# ESP32-C5-LP register map
Vendor: ESPRESSIF SYSTEMS (SHANGHAI) CO., LTD.; Series: ESP32 C-Series; File version: 1
CPU: RV32IMAC r0p0, little endian, no MPU, no FPU, 0 interrupt priority bits
Address unit: 32 bits
Registers are 32-bit, read-write, reset 0x0 unless marked. A register's access mark holds for its fields unless they carry their own. Offsets are from the block's base; [hi:lo] are bit positions; {n}, {i} and the like mark numbered series.

## LP_APM0 — LP_APM0 Peripheral
Base 0x600B3800
0x00 REGION_FILTER_EN reset 0x1 — Region filter enable register
  [3:0] REGION_FILTER_EN — Configure bit 0 (0-3) to enable region 0.\\ 0: disable \\ 1: enable \\
{0x4+0xC*i} REGION{i}_ADDR_START (i=0..3) — Region address register
  [31:0] REGION_ADDR_START — Configures start address of region %s.
{0x8+0xC*i} REGION{i}_ADDR_END (i=0..3) reset 0xFFFFFFFF — Region address register
  [31:0] REGION_ADDR_END — Configures end address of region %s.
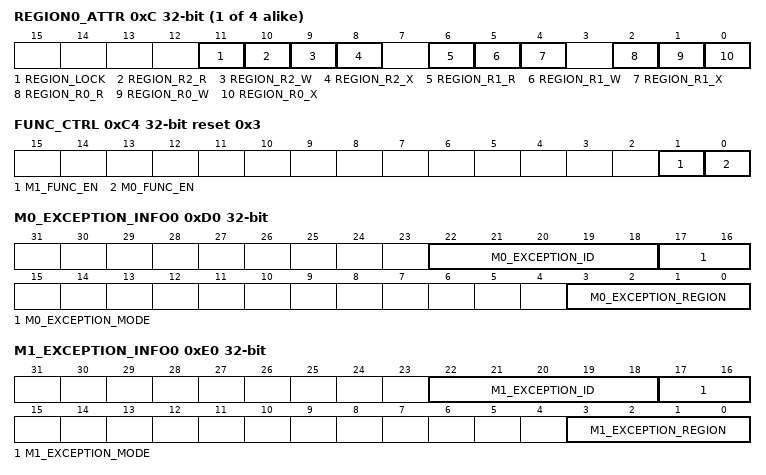
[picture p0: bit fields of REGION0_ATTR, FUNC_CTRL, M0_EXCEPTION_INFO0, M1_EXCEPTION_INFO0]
{0xC+0xC*i} REGION{i}_ATTR (i=0..3) — Region access authority attribute register
  [11] REGION_LOCK — Set 1 to lock region0 configuration
  [10] REGION_R2_R — Configures the read authority of REE_MODE 2 in region %s.
  [9] REGION_R2_W — Configures the write authority of REE_MODE 2 in region %s.
  [8] REGION_R2_X — Configures the execution authority of REE_MODE 2 in region %s.
  [6] REGION_R1_R — Configures the read authority of REE_MODE 1 in region %s.
  [5] REGION_R1_W — Configures the write authority of REE_MODE 1 in region %s.
  [4] REGION_R1_X — Configures the execution authority of REE_MODE 1 in region %s.
  [2] REGION_R0_R — Configures the read authority of REE_MODE 0 in region %s.
  [1] REGION_R0_W — Configures the write authority of REE_MODE 0 in region %s.
  [0] REGION_R0_X — Configures the execution authority of REE_MODE 0 in region %s.
0xC4 FUNC_CTRL reset 0x3 — APM function control register
  [1] M1_FUNC_EN — PMS M1 function enable
  [0] M0_FUNC_EN — PMS M0 function enable
0xC8 M0_STATUS ro
  [1:0] M0_EXCEPTION_STATUS — Represents exception status.\\ bit0: 1 represents authority_exception \\ bit1: 1 represents space_exception \\
0xCC M0_STATUS_CLR wo — M0 status clear register
  [0] M0_EXCEPTION_STATUS_CLR — Configures to clear exception status.
0xD0 M0_EXCEPTION_INFO0 ro
  [22:18] M0_EXCEPTION_ID — Represents exception id information.
  [17:16] M0_EXCEPTION_MODE — Represents exception mode.
  [3:0] M0_EXCEPTION_REGION — Represents exception region.
0xD4 M0_EXCEPTION_INFO1 ro
  [31:0] M0_EXCEPTION_ADDR — Represents exception addr.
0xD8 M1_STATUS ro
  [1:0] M1_EXCEPTION_STATUS — Represents exception status.\\ bit0: 1 represents authority_exception \\ bit1: 1 represents space_exception \\
0xDC M1_STATUS_CLR wo — M1 status clear register
  [0] M1_EXCEPTION_STATUS_CLR — Configures to clear exception status.
0xE0 M1_EXCEPTION_INFO0 ro
  [22:18] M1_EXCEPTION_ID — Represents exception id information.
  [17:16] M1_EXCEPTION_MODE — Represents exception mode.
  [3:0] M1_EXCEPTION_REGION — Represents exception region.
0xE4 M1_EXCEPTION_INFO1 ro
  [31:0] M1_EXCEPTION_ADDR — Represents exception addr.
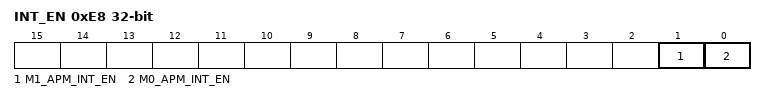
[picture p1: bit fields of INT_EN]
0xE8 INT_EN — APM interrupt enable register
  [1] M1_APM_INT_EN — Configures to enable APM M1 interrupt.\\ 0: disable \\ 1: enable \\
  [0] M0_APM_INT_EN — Configures to enable APM M0 interrupt.\\ 0: disable \\ 1: enable \\
0xEC CLOCK_GATE reset 0x1 — clock gating register
  [0] CLK_EN — Configures whether to keep the clock always on.\\ 0: enable automatic clock gating \\ 1: keep the clock always on \\
0xFC DATE reset 0x2212160 — Version control register
  [27:0] DATE — Version control register.

## LP_I2C_ANA_MST — LP_I2C_ANA_MST Peripheral
Base 0x600B2400
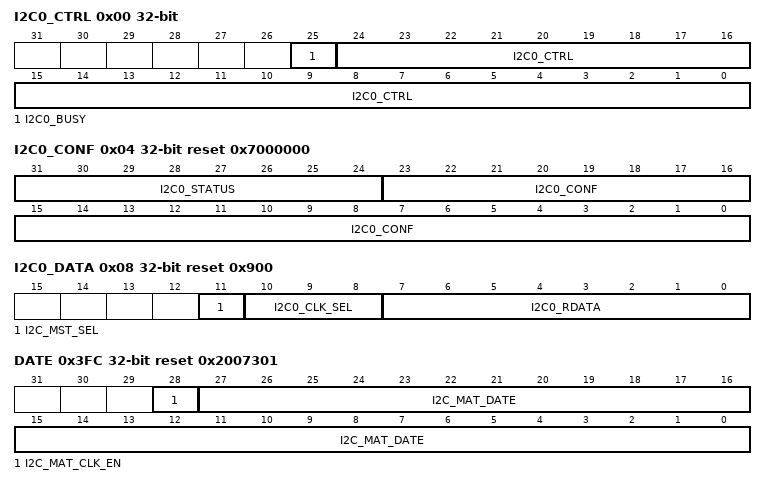
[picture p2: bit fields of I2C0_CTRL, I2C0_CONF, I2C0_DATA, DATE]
0x00 I2C0_CTRL access per field — need_des
  [25] I2C0_BUSY ro — need_des
  [24:0] I2C0_CTRL rw — need_des
0x04 I2C0_CONF access per field reset 0x7000000 — need_des
  [31:24] I2C0_STATUS ro — reserved
  [23:0] I2C0_CONF rw — need_des
0x08 I2C0_DATA access per field reset 0x900 — need_des
  [11] I2C_MST_SEL rw — need des
  [10:8] I2C0_CLK_SEL rw — need_des
  [7:0] I2C0_RDATA ro — need_des
0x0C ANA_CONF1 — need_des
  [23:0] ANA_CONF1
0x10 NOUSE — need_des
  [31:0] I2C_MST_NOUSE
0x14 DEVICE_EN — need_des
  [11:0] I2C_DEVICE_EN
0x3FC DATE reset 0x2007301 — need_des
  [28] I2C_MAT_CLK_EN — need_des
  [27:0] I2C_MAT_DATE — need_des

## LP_IO_MUX — Low-power Input/Output Multiplexer
Base 0x600B4000
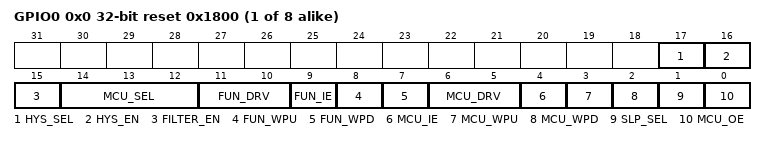
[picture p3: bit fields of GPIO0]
{0x0+4i} GPIO{i} (i=0..7) reset 0x1800 — LP_IO_MUX Configure Register for pad GPIO{i}
  [17] HYS_SEL — Configures to choose the signal for enabling the hysteresis function for GPIO%s. \\ 0: Choose the output enable signal of eFuse\\ 1: Choose the output enable signal of IO_MUX_GPIO%s_HYS_EN\\
  [16] HYS_EN — Configures whether or not to enable the hysteresis function of the pin when IO_MUX_GPIO%s_HYS_SEL is set to 1.\\ 0: Disable\\ 1: Enable\\
  [15] FILTER_EN — Configures whether or not to enable filter for pin input signals.\\ 0: Disable\\ 1: Enable\\
  [14:12] MCU_SEL — Configures to select the LP IO MUX function for GPIO%s in normal execution mode.\\ 0: Select Function 0\\ 1: Select Function 1\\ ......\\
  [11:10] FUN_DRV — Configures the drive strength of GPIO%s in normal execution mode.\\ 0: ~5 mA\\ 1: ~10 mA\\ 2: ~20 mA\\ 3: ~40 mA\\
  [9] FUN_IE — Configures whether or not to enable the input of GPIO%s in normal execution mode.\\ 0: Not enable\\ 1: Enable\\
  [8] FUN_WPU — Configures whether or not to enable the pull-up resistor of GPIO%s in normal execution mode.\\ 0: Not enable\\ 1: Enable\\
  [7] FUN_WPD — Configures whether or not to enable the pull-down resistor of GPIO%s in normal execution mode.\\ 0: Not enable\\ 1: Enable\\
  [6:5] MCU_DRV — Configures the drive strength of GPIO%s during sleep mode. \\ 0: ~5 mA\\ 1: ~10 mA\\ 2: ~20 mA\\ 3: ~40 mA\\
  [4] MCU_IE — Configures whether or not to enable the input of GPIO%s during sleep mode.\\ 0: Not enable\\ 1: Enable\\
  [3] MCU_WPU — Configures whether or not to enable the pull-up resistor of GPIO%s during sleep mode.\\ 0: Not enable\\ 1: Enable\\
  [2] MCU_WPD — Configures whether or not to enable the pull-down resistor of GPIO%s during sleep mode. \\ 0: Not enable\\ 1: Enable\\
  [1] SLP_SEL — Configures whether or not to enable the sleep mode for GPIO%s.\\ 0: Not enable\\ 1: Enable\\
  [0] MCU_OE — Configures whether or not to enable the output of GPIO%s during sleep mode.\\ 0: Not enable\\ 1: Enable\\
0x1FC DATE reset 0x2211270 — LP_IO_MUX Version Control Register
  [27:0] REG_DATE — Version control register. \\

## LP_TEE — Low-power Trusted Execution Environment
Base 0x600B3400
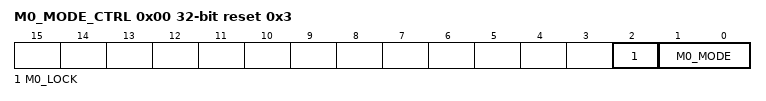
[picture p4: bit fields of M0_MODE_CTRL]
0x00 M0_MODE_CTRL reset 0x3 — TEE mode control register
  [2] M0_LOCK — Set 1 to lock m0 tee configuration
  [1:0] M0_MODE — Configures M0 security level mode.\\ 0: tee_mode \\ 1: ree_mode0 \\ 2: ree_mode1 \\ 3: ree_mode2 \\
0x04 CLOCK_GATE reset 0x1 — Clock gating register
  [0] CLK_EN — Configures whether to keep the clock always on.\\ 0: enable automatic clock gating \\ 1: keep the clock always on \\
0x90 FORCE_ACC_HP — Force access to hpmem configuration register
  [0] FORCE_ACC_HPMEM_EN — Configures whether to allow LP CPU to force access to HP_MEM regardless of permission management.\\ 0: disable force access HP_MEM \\ 1: enable force access HP_MEM \\
0xFC DATE reset 0x2212160 — Version control register
  [27:0] DATE
